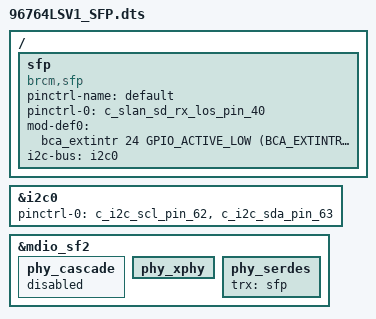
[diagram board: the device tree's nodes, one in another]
#include "96764LSV1.dts"

/ {


	sfp: sfp {
		compatible = "brcm,sfp";
		pinctrl-name = "default";
		pinctrl-0 = <&c_slan_sd_rx_los_pin_40>;
		mod-def0 = <&bca_extintr 24 GPIO_ACTIVE_LOW (BCA_EXTINTR_TYPE_BOTH_EDGE | BCA_EXTINTR_TYPE_SENSE_EDGE)>;
		i2c-bus = <&i2c0>;
		status = "okay";
	};
};

&i2c0 {
	pinctrl-names = "default";
	pinctrl-0 = <&c_i2c_scl_pin_62 &c_i2c_sda_pin_63>;
	status = "okay";
};

&mdio_sf2 {

	phy_cascade {
		status = "disabled";
	};
       /* port phy mapping:
            port_imp -8#0- port_xhy <----> phy_xphy
                      # #
                      ##5- port_sgmii <-> phy_serdes - sfp
         */
	phy_xphy {
		status = "okay";
	};
	phy_serdes {
		trx = <&sfp>;
		status = "okay";
		/delete-property/ phy-handle;
	};
};


